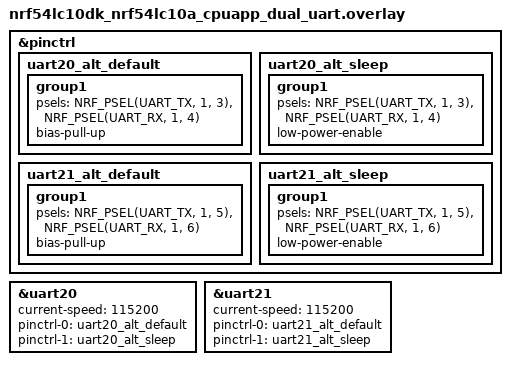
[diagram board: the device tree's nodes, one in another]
/*
 * Copyright (c) 2026 Nordic Semiconductor ASA
 *
 * SPDX-License-Identifier: LicenseRef-Nordic-5-Clause
 */

/*
 * Loopbacks:
 * uart20: P1.03 <-> P1.04
 * uart21: P1.05 <-> P1.06
 */

&pinctrl {
	uart20_alt_default: uart20_alt_default {
		group1 {
			psels = <NRF_PSEL(UART_TX, 1, 3)>,
				<NRF_PSEL(UART_RX, 1, 4)>;
			bias-pull-up;
		};
	};

	uart20_alt_sleep: uart20_alt_sleep {
		group1 {
			psels = <NRF_PSEL(UART_TX, 1, 3)>,
				<NRF_PSEL(UART_RX, 1, 4)>;
			low-power-enable;
		};
	};

	uart21_alt_default: uart21_alt_default {
		group1 {
			psels = <NRF_PSEL(UART_TX, 1, 5)>,
				<NRF_PSEL(UART_RX, 1, 6)>;
			bias-pull-up;
		};
	};

	uart21_alt_sleep: uart21_alt_sleep {
		group1 {
			psels = <NRF_PSEL(UART_TX, 1, 5)>,
				<NRF_PSEL(UART_RX, 1, 6)>;
			low-power-enable;
		};
	};
};

dut: &uart20 {
	status = "okay";
	current-speed = <115200>;
	pinctrl-0 = <&uart20_alt_default>;
	pinctrl-1 = <&uart20_alt_sleep>;
	pinctrl-names = "default", "sleep";
};

dut_aux: &uart21 {
	status = "okay";
	current-speed = <115200>;
	pinctrl-0 = <&uart21_alt_default>;
	pinctrl-1 = <&uart21_alt_sleep>;
	pinctrl-names = "default", "sleep";
};
